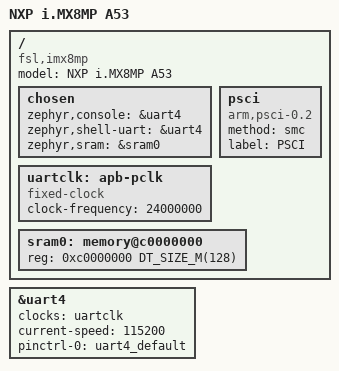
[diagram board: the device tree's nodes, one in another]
/*
 * Copyright 2021 NXP
 *
 * SPDX-License-Identifier: Apache-2.0
 */

/dts-v1/;

#include <nxp/nxp_imx8mp_a53.dtsi>
#include "imx8mp_evk-pinctrl.dtsi"

/ {
	model = "NXP i.MX8MP A53";
	compatible = "fsl,imx8mp";

	chosen {
		zephyr,console = &uart4;
		zephyr,shell-uart = &uart4;
		zephyr,sram = &sram0;
	};

	uartclk: apb-pclk {
		compatible = "fixed-clock";
		clock-frequency = <24000000>;
		#clock-cells = <0>;
	};

	psci {
		compatible = "arm,psci-0.2";
		method = "smc";
		label = "PSCI";
	};

	sram0: memory@c0000000 {
		reg = <0xc0000000 DT_SIZE_M(128)>;
	};

};

&uart4 {
	status = "okay";
	clocks = <&uartclk>;
	current-speed = <115200>;
	pinctrl-0 = <&uart4_default>;
	pinctrl-names = "default";
};
